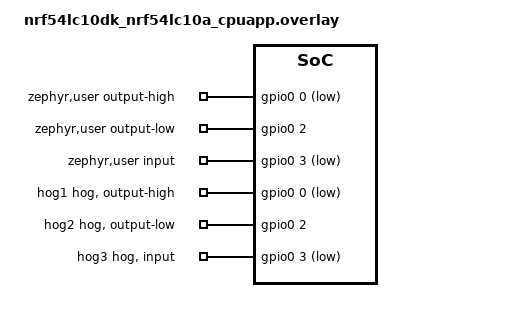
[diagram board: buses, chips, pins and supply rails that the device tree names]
/*
 * Copyright (c) 2026 Nordic Semiconductor ASA
 *
 * SPDX-License-Identifier: LicenseRef-Nordic-5-Clause
 */

#include <zephyr/dt-bindings/gpio/gpio.h>

/ {
	zephyr,user {
		output-high-gpios = <&gpio0 0 GPIO_ACTIVE_LOW>;
		output-low-gpios = <&gpio0 2 GPIO_ACTIVE_HIGH>;
		input-gpios = <&gpio0 3 GPIO_ACTIVE_LOW>;
	};
};

&gpio0 {
	status = "okay";

	hog1 {
		gpio-hog;
		gpios = <0 GPIO_ACTIVE_LOW>;
		output-high;
	};

	hog2 {
		gpio-hog;
		gpios = <2 GPIO_ACTIVE_HIGH>;
		output-low;
	};

	hog3 {
		gpio-hog;
		gpios = <3 GPIO_ACTIVE_LOW>;
		input;
	};
};

&gpiote20 {
	status = "okay";
};
